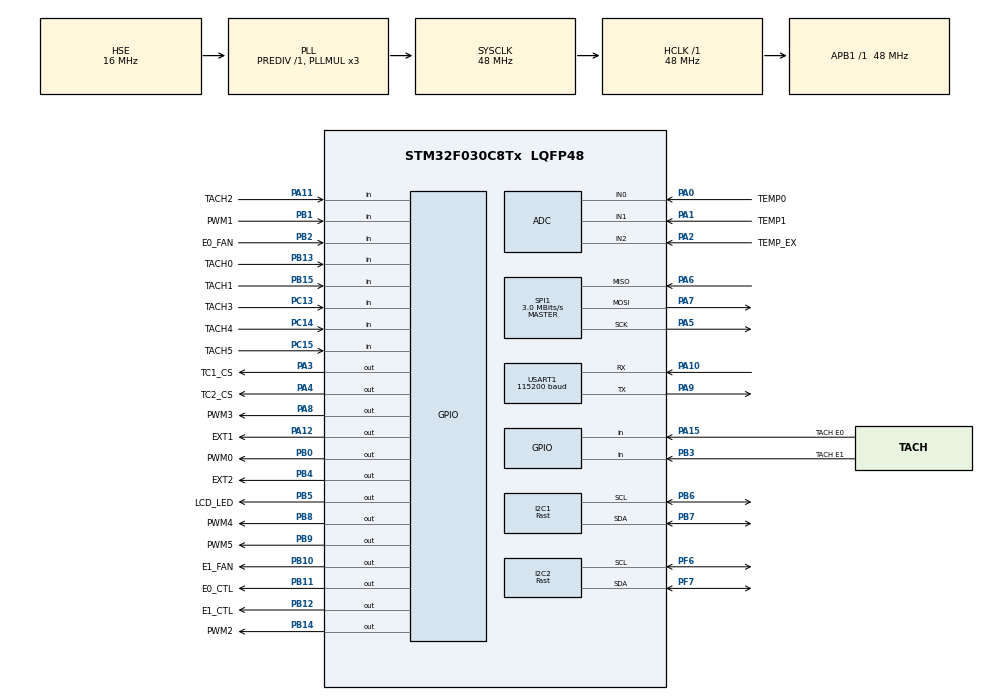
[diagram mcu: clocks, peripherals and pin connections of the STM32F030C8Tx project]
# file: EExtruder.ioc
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ADC.ContinuousConvMode=ENABLE
ADC.DMAContinuousRequests=ENABLE
ADC.EOCSelection=ADC_EOC_SEQ_CONV
ADC.SamplingTime=ADC_SAMPLETIME_239CYCLES_5
Dma.ADC.0.Direction=DMA_PERIPH_TO_MEMORY
Dma.ADC.0.Instance=DMA1_Channel1
Dma.ADC.0.MemDataAlignment=DMA_MDATAALIGN_HALFWORD
Dma.ADC.0.MemInc=DMA_MINC_ENABLE
Dma.ADC.0.Mode=DMA_NORMAL
Dma.ADC.0.PeriphDataAlignment=DMA_PDATAALIGN_HALFWORD
Dma.ADC.0.PeriphInc=DMA_PINC_DISABLE
Dma.ADC.0.Priority=DMA_PRIORITY_HIGH
Dma.Request0=ADC
FREERTOS.Tasks01=defaultTask,0,128,StartDefaultTask,Default,NULL
FREERTOS.configTIMER_QUEUE_LENGTH=4
FREERTOS.configTIMER_TASK_STACK_DEPTH=128
FREERTOS.configTOTAL_HEAP_SIZE=4096
FREERTOS.configUSE_TIMERS=1
I2C1.I2C_Speed_Mode=I2C_Fast
I2C1.Timing=0x2010091A
I2C2.I2C_Speed_Mode=I2C_Fast
I2C2.Timing=0x2010091A
Mcu.Family=STM32F0
Mcu.Name=STM32F030C8Tx
Mcu.Package=LQFP48
NVIC.DMA1_Channel1_IRQn=true\:3\:0\:false\:false\:true\:true\:false
NVIC.TIM14_IRQn=true\:3\:0\:false\:false\:true\:true\:true
NVIC.TIM3_IRQn=true\:3\:0\:false\:false\:true\:true\:true
NVIC.TIM6_IRQn=true\:0\:0\:false\:false\:true\:false\:false
NVIC.TimeBase=TIM6_IRQn
NVIC.TimeBaseIP=TIM6
NVIC.USART1_IRQn=true\:3\:0\:false\:false\:true\:true\:true
PA0.GPIO_Label=TEMP0
PA0.Mode=IN0
PA0.Signal=ADC_IN0
PA1.GPIO_Label=TEMP1
PA1.Mode=IN1
PA1.Signal=ADC_IN1
PA10.Mode=Asynchronous
PA10.Signal=USART1_RX
PA11.GPIO_Label=TACH2
PA11.Signal=GPIO_Input
PA12.GPIO_Label=EXT1
PA12.Signal=GPIO_Output
PA13.Mode=Serial_Wire
PA13.Signal=SYS_SWDIO
PA14.Mode=Serial_Wire
PA14.Signal=SYS_SWCLK
PA15.GPIO_Label=TACH E0
PA15.Signal=GPIO_Input
PA2.GPIO_Label=TEMP_EX
PA2.Mode=IN2
PA2.Signal=ADC_IN2
PA3.GPIO_Label=TC1_CS
PA3.Signal=GPIO_Output
PA4.GPIO_Label=TC2_CS
PA4.Signal=GPIO_Output
PA5.Mode=Full_Duplex_Master
PA5.Signal=SPI1_SCK
PA6.Mode=Full_Duplex_Master
PA6.Signal=SPI1_MISO
PA7.Mode=Full_Duplex_Master
PA7.Signal=SPI1_MOSI
PA8.GPIO_Label=PWM3
PA8.Signal=GPIO_Output
PA9.Mode=Asynchronous
PA9.Signal=USART1_TX
PB0.GPIO_Label=PWM0
PB0.Signal=GPIO_Output
PB1.GPIO_Label=PWM1
PB1.Signal=GPIO_Input
PB10.GPIO_Label=E1_FAN
PB10.Signal=GPIO_Output
PB11.GPIO_Label=E0_CTL
PB11.PinState=GPIO_PIN_SET
PB11.Signal=GPIO_Output
PB12.GPIO_Label=E1_CTL
PB12.PinState=GPIO_PIN_SET
PB12.Signal=GPIO_Output
PB13.GPIO_Label=TACH0
PB13.Signal=GPIO_Input
PB14.GPIO_Label=PWM2
PB14.Signal=GPIO_Output
PB15.GPIO_Label=TACH1
PB15.Signal=GPIO_Input
PB2.GPIO_Label=E0_FAN
PB2.Signal=GPIO_Input
PB3.GPIO_Label=TACH E1
PB3.Signal=GPIO_Input
PB4.GPIO_Label=EXT2
PB4.Signal=GPIO_Output
PB5.GPIO_Label=LCD_LED
PB5.Signal=GPIO_Output
PB6.Mode=I2C
PB6.Signal=I2C1_SCL
PB7.Mode=I2C
PB7.Signal=I2C1_SDA
PB8.GPIO_Label=PWM4
PB8.Signal=GPIO_Output
PB9.GPIO_Label=PWM5
PB9.Signal=GPIO_Output
PC13.GPIO_Label=TACH3
PC13.Signal=GPIO_Input
PC14-OSC32_IN.GPIO_Label=TACH4
PC14-OSC32_IN.Signal=GPIO_Input
PC15-OSC32_OUT.GPIO_Label=TACH5
PC15-OSC32_OUT.Signal=GPIO_Input
PF0-OSC_IN.Mode=HSE-External-Oscillator
PF0-OSC_IN.Signal=RCC_OSC_IN
PF1-OSC_OUT.Mode=HSE-External-Oscillator
PF1-OSC_OUT.Signal=RCC_OSC_OUT
PF6.Mode=I2C
PF6.Signal=I2C2_SCL
PF7.Mode=I2C
PF7.Signal=I2C2_SDA
ProjectManager.HeapSize=0x200
ProjectManager.StackSize=0x200
ProjectManager.TargetToolchain=Makefile
RCC.AHBFreq_Value=48000000
RCC.APB1Freq_Value=48000000
RCC.APB1TimFreq_Value=48000000
RCC.HCLKFreq_Value=48000000
RCC.HSE_VALUE=16000000
RCC.I2c1ClockSelection=RCC_I2C1CLKSOURCE_SYSCLK
RCC.PLLMUL=RCC_PLL_MUL3
RCC.PLLSourceVirtual=RCC_PLLSOURCE_HSE
RCC.SYSCLKFreq_VALUE=48000000
RCC.SYSCLKSource=RCC_SYSCLKSOURCE_PLLCLK
SPI1.BaudRatePrescaler=SPI_BAUDRATEPRESCALER_16
SPI1.CalculateBaudRate=3.0 MBits/s
SPI1.DataSize=SPI_DATASIZE_8BIT
SPI1.Direction=SPI_DIRECTION_2LINES
SPI1.Mode=SPI_MODE_MASTER
SPI1.VirtualType=VM_MASTER
TIM14.AutoReloadPreload=TIM_AUTORELOAD_PRELOAD_ENABLE
TIM14.Period=997
TIM14.Prescaler=480
TIM3.AutoReloadPreload=TIM_AUTORELOAD_PRELOAD_ENABLE
TIM3.Period=489
TIM3.Prescaler=48
USART1.BaudRate=115200
USART1.VirtualMode-Asynchronous=VM_ASYNC
VP_ADC_TempSens_Input.Mode=IN-TempSens
VP_ADC_Vref_Input.Mode=IN-Vrefint
VP_FREERTOS_VS_ENABLE.Mode=Enabled
VP_SYS_VS_tim6.Mode=TIM6
VP_TIM14_VS_ClockSourceINT.Mode=Enable_Timer
VP_TIM3_VS_ClockSourceINT.Mode=Internal
board=custom

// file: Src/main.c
/* USER CODE BEGIN Header */
/**
  ******************************************************************************
  * @file           : main.c
  * @brief          : Main program body
  ******************************************************************************
  * This notice applies to any and all portions of this file
  * that are not between comment pairs USER CODE BEGIN and
  * USER CODE END. Other portions of this file, whether
  * inserted by the user or by software development tools
  * are owned by their respective copyright owners.
  *
  * Copyright (c) 2018 STMicroelectronics International N.V.
  * All rights reserved.
  *
  * Redistribution and use in source and binary forms, with or without
  * modification, are permitted, provided that the following conditions are met:
  *
  * 1. Redistribution of source code must retain the above copyright notice,
  *    this list of conditions and the following disclaimer.
  * 2. Redistributions in binary form must reproduce the above copyright notice,
  *    this list of conditions and the following disclaimer in the documentation
  *    and/or other materials provided with the distribution.
  * 3. Neither the name of STMicroelectronics nor the names of other
  *    contributors to this software may be used to endorse or promote products
  *    derived from this software without specific written permission.
  * 4. This software, including modifications and/or derivative works of this
  *    software, must execute solely and exclusively on microcontroller or
  *    microprocessor devices manufactured by or for STMicroelectronics.
  * 5. Redistribution and use of this software other than as permitted under
  *    this license is void and will automatically terminate your rights under
  *    this license.
  *
  * THIS SOFTWARE IS PROVIDED BY STMICROELECTRONICS AND CONTRIBUTORS "AS IS"
  * AND ANY EXPRESS, IMPLIED OR STATUTORY WARRANTIES, INCLUDING, BUT NOT
  * LIMITED TO, THE IMPLIED WARRANTIES OF MERCHANTABILITY, FITNESS FOR A
  * PARTICULAR PURPOSE AND NON-INFRINGEMENT OF THIRD PARTY INTELLECTUAL PROPERTY
  * RIGHTS ARE DISCLAIMED TO THE FULLEST EXTENT PERMITTED BY LAW. IN NO EVENT
  * SHALL STMICROELECTRONICS OR CONTRIBUTORS BE LIABLE FOR ANY DIRECT, INDIRECT,
  * INCIDENTAL, SPECIAL, EXEMPLARY, OR CONSEQUENTIAL DAMAGES (INCLUDING, BUT NOT
  * LIMITED TO, PROCUREMENT OF SUBSTITUTE GOODS OR SERVICES; LOSS OF USE, DATA,
  * OR PROFITS; OR BUSINESS INTERRUPTION) HOWEVER CAUSED AND ON ANY THEORY OF
  * LIABILITY, WHETHER IN CONTRACT, STRICT LIABILITY, OR TORT (INCLUDING
  * NEGLIGENCE OR OTHERWISE) ARISING IN ANY WAY OUT OF THE USE OF THIS SOFTWARE,
  * EVEN IF ADVISED OF THE POSSIBILITY OF SUCH DAMAGE.
  *
  ******************************************************************************
  */
/* USER CODE END Header */

#include "main.h"
#include "cmsis_os.h"
#include "adc.h"
#include "dma.h"
#include "i2c.h"
#include "spi.h"
#include "tim.h"
#include "usart.h"
#include "gpio.h"

void SystemClock_Config(void);
void MX_FREERTOS_Init(void);

int main(void)
{

  /* MCU Configuration--------------------------------------------------------*/

  /* Reset of all peripherals, Initializes the Flash interface and the Systick. */
  HAL_Init();

  /* Configure the system clock */
  SystemClock_Config();

  /* Initialize all configured peripherals */
  MX_GPIO_Init();
  MX_DMA_Init();
  MX_ADC_Init();
  MX_I2C1_Init();
  MX_I2C2_Init();
  MX_SPI1_Init();
  MX_USART1_UART_Init();
  MX_TIM3_Init();
  MX_TIM14_Init();
  /* USER CODE BEGIN 2 */
  if (HAL_ADCEx_Calibration_Start(&hadc) != HAL_OK)
  {
    Error_Handler();
  }
  /* USER CODE END 2 */

  /* Call init function for freertos objects (in freertos.c) */
  MX_FREERTOS_Init();

  /* Start scheduler */
  osKernelStart();

  /* We should never get here as control is now taken by the scheduler */

  /* Infinite loop */
  while (1)
  {

  }
}

void SystemClock_Config(void)
{
  RCC_OscInitTypeDef RCC_OscInitStruct = {0};
  RCC_ClkInitTypeDef RCC_ClkInitStruct = {0};
  RCC_PeriphCLKInitTypeDef PeriphClkInit = {0};

  /**Initializes the CPU, AHB and APB busses clocks
  */
  RCC_OscInitStruct.OscillatorType = RCC_OSCILLATORTYPE_HSI14|RCC_OSCILLATORTYPE_HSE;
  RCC_OscInitStruct.HSEState = RCC_HSE_ON;
  RCC_OscInitStruct.HSI14State = RCC_HSI14_ON;
  RCC_OscInitStruct.HSI14CalibrationValue = 16;
  RCC_OscInitStruct.PLL.PLLState = RCC_PLL_ON;
  RCC_OscInitStruct.PLL.PLLSource = RCC_PLLSOURCE_HSE;
  RCC_OscInitStruct.PLL.PLLMUL = RCC_PLL_MUL3;
  RCC_OscInitStruct.PLL.PREDIV = RCC_PREDIV_DIV1;
  if (HAL_RCC_OscConfig(&RCC_OscInitStruct) != HAL_OK)
  {
    Error_Handler();
  }
  /**Initializes the CPU, AHB and APB busses clocks
  */
  RCC_ClkInitStruct.ClockType = RCC_CLOCKTYPE_HCLK|RCC_CLOCKTYPE_SYSCLK
                              |RCC_CLOCKTYPE_PCLK1;
  RCC_ClkInitStruct.SYSCLKSource = RCC_SYSCLKSOURCE_PLLCLK;
  RCC_ClkInitStruct.AHBCLKDivider = RCC_SYSCLK_DIV1;
  RCC_ClkInitStruct.APB1CLKDivider = RCC_HCLK_DIV1;

  if (HAL_RCC_ClockConfig(&RCC_ClkInitStruct, FLASH_LATENCY_1) != HAL_OK)
  {
    Error_Handler();
  }
  PeriphClkInit.PeriphClockSelection = RCC_PERIPHCLK_USART1|RCC_PERIPHCLK_I2C1;
  PeriphClkInit.Usart1ClockSelection = RCC_USART1CLKSOURCE_PCLK1;
  PeriphClkInit.I2c1ClockSelection = RCC_I2C1CLKSOURCE_SYSCLK;
  if (HAL_RCCEx_PeriphCLKConfig(&PeriphClkInit) != HAL_OK)
  {
    Error_Handler();
  }
}

void HAL_TIM_PeriodElapsedCallback(TIM_HandleTypeDef *htim)
{
  if (htim->Instance == TIM6) {
    HAL_IncTick();
  }
}

void Error_Handler(void)
{
  /* USER CODE BEGIN Error_Handler_Debug */
  if (SerialOK) {
    HAL_UART_Transmit(&huart1, (uint8_t*)"Error!!!\n\r", 10, 0xffff);
  }
  while(1) {
    asm ("bkpt 255");
  }
  /* USER CODE END Error_Handler_Debug */
}

/************************ (C) COPYRIGHT STMicroelectronics *****END OF FILE****/

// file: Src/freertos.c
/* USER CODE BEGIN Header */
/**
  ******************************************************************************
  * File Name          : freertos.c
  * Description        : Code for freertos applications
  ******************************************************************************
  * This notice applies to any and all portions of this file
  * that are not between comment pairs USER CODE BEGIN and
  * USER CODE END. Other portions of this file, whether
  * inserted by the user or by software development tools
  * are owned by their respective copyright owners.
  *
  * Copyright (c) 2018 STMicroelectronics International N.V.
  * All rights reserved.
  *
  * Redistribution and use in source and binary forms, with or without
  * modification, are permitted, provided that the following conditions are met:
  *
  * 1. Redistribution of source code must retain the above copyright notice,
  *    this list of conditions and the following disclaimer.
  * 2. Redistributions in binary form must reproduce the above copyright notice,
  *    this list of conditions and the following disclaimer in the documentation
  *    and/or other materials provided with the distribution.
  * 3. Neither the name of STMicroelectronics nor the names of other
  *    contributors to this software may be used to endorse or promote products
  *    derived from this software without specific written permission.
  * 4. This software, including modifications and/or derivative works of this
  *    software, must execute solely and exclusively on microcontroller or
  *    microprocessor devices manufactured by or for STMicroelectronics.
  * 5. Redistribution and use of this software other than as permitted under
  *    this license is void and will automatically terminate your rights under
  *    this license.
  *
  * THIS SOFTWARE IS PROVIDED BY STMICROELECTRONICS AND CONTRIBUTORS "AS IS"
  * AND ANY EXPRESS, IMPLIED OR STATUTORY WARRANTIES, INCLUDING, BUT NOT
  * LIMITED TO, THE IMPLIED WARRANTIES OF MERCHANTABILITY, FITNESS FOR A
  * PARTICULAR PURPOSE AND NON-INFRINGEMENT OF THIRD PARTY INTELLECTUAL PROPERTY
  * RIGHTS ARE DISCLAIMED TO THE FULLEST EXTENT PERMITTED BY LAW. IN NO EVENT
  * SHALL STMICROELECTRONICS OR CONTRIBUTORS BE LIABLE FOR ANY DIRECT, INDIRECT,
  * INCIDENTAL, SPECIAL, EXEMPLARY, OR CONSEQUENTIAL DAMAGES (INCLUDING, BUT NOT
  * LIMITED TO, PROCUREMENT OF SUBSTITUTE GOODS OR SERVICES; LOSS OF USE, DATA,
  * OR PROFITS; OR BUSINESS INTERRUPTION) HOWEVER CAUSED AND ON ANY THEORY OF
  * LIABILITY, WHETHER IN CONTRACT, STRICT LIABILITY, OR TORT (INCLUDING
  * NEGLIGENCE OR OTHERWISE) ARISING IN ANY WAY OUT OF THE USE OF THIS SOFTWARE,
  * EVEN IF ADVISED OF THE POSSIBILITY OF SUCH DAMAGE.
  *
  ******************************************************************************
  */
/* USER CODE END Header */

#include "FreeRTOS.h"
#include "task.h"
#include "main.h"
#include "cmsis_os.h"

/* USER CODE BEGIN Includes */
#include "task_start.h"
/* USER CODE END Includes */

osThreadId defaultTaskHandle;

void StartDefaultTask(void const * argument);

void MX_FREERTOS_Init(void); /* (MISRA C 2004 rule 8.1) */

void MX_FREERTOS_Init(void) {

  /* Create the thread(s) */
  /* definition and creation of defaultTask */
  osThreadDef(defaultTask, StartDefaultTask, osPriorityNormal, 0, 256);
  defaultTaskHandle = osThreadCreate(osThread(defaultTask), NULL);

}

void StartDefaultTask(void const * argument)
{

  /* USER CODE BEGIN StartDefaultTask */
  taskStart();
  /* USER CODE END StartDefaultTask */
}

/************************ (C) COPYRIGHT STMicroelectronics *****END OF FILE****/
